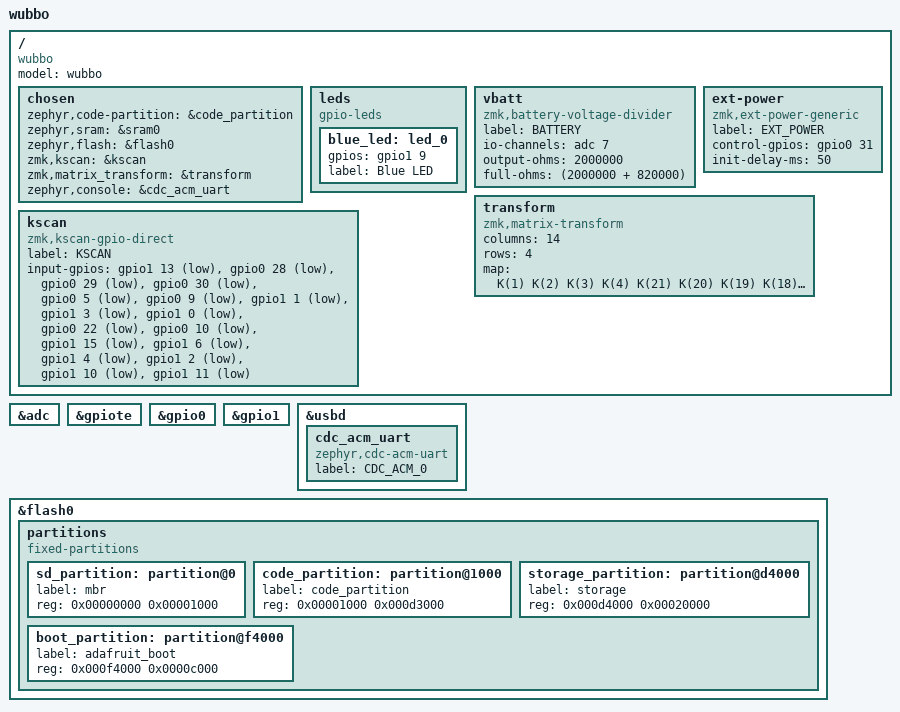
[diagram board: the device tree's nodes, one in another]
/*
 * Copyright (c) 2022 The ZMK Contributors
 *
 * SPDX-License-Identifier: MIT
 */

/dts-v1/;
#include <nordic/nrf52840_qiaa.dtsi>
#include <dt-bindings/zmk/matrix_transform.h>

/ {
	model = "wubbo";
	compatible = "wubbo";

	chosen {
		zephyr,code-partition = &code_partition;
		zephyr,sram = &sram0;
		zephyr,flash = &flash0;
		zmk,kscan = &kscan;
		zmk,matrix_transform = &transform;
		zephyr,console = &cdc_acm_uart;
	};

	leds {
		compatible = "gpio-leds";
		blue_led: led_0 {
			gpios = <&gpio1 9 GPIO_ACTIVE_HIGH>;
			label = "Blue LED";
		};
	};

	vbatt {
		compatible = "zmk,battery-voltage-divider";
		label = "BATTERY";
		io-channels = <&adc 7>;
		output-ohms = <2000000>;
		full-ohms = <(2000000 + 820000)>;
	};

	ext-power {
		compatible = "zmk,ext-power-generic";
		label = "EXT_POWER";
		control-gpios = <&gpio0 31 GPIO_ACTIVE_HIGH>;
		init-delay-ms = <50>;
	};

#define K(n) RC(0,n)
	transform: transform {
		compatible = "zmk,matrix-transform";
		columns = <14>;
		rows = <4>;

		map = <
            K(1)  K(2)  K(3)  K(4)                 K(21) K(20) K(19) K(18) 
K(0)  K(5)  K(6)  K(7)  K(8)  K(9)                 K(26) K(25) K(24) K(23) K(22) K(17)
      K(10) K(11) K(12) K(13) K(14)                K(31) K(30) K(29) K(28) K(27)
                              K(15) K(16)    K(33) K(32)
	>;
	};
	
	kscan: kscan {
		compatible = "zmk,kscan-gpio-direct";
		label = "KSCAN";

        input-gpios
            = <&gpio1 13 (GPIO_ACTIVE_LOW | GPIO_PULL_UP)>
            , <&gpio0 28 (GPIO_ACTIVE_LOW | GPIO_PULL_UP)>
            , <&gpio0 29 (GPIO_ACTIVE_LOW | GPIO_PULL_UP)>
            , <&gpio0 30 (GPIO_ACTIVE_LOW | GPIO_PULL_UP)>
            , <&gpio0  5 (GPIO_ACTIVE_LOW | GPIO_PULL_UP)>

            , <&gpio0  9 (GPIO_ACTIVE_LOW | GPIO_PULL_UP)>
            , <&gpio1  1 (GPIO_ACTIVE_LOW | GPIO_PULL_UP)>
            , <&gpio1  3 (GPIO_ACTIVE_LOW | GPIO_PULL_UP)>
            , <&gpio1  0 (GPIO_ACTIVE_LOW | GPIO_PULL_UP)>
            , <&gpio0 22 (GPIO_ACTIVE_LOW | GPIO_PULL_UP)>

            , <&gpio0  10 (GPIO_ACTIVE_LOW | GPIO_PULL_UP)>
            , <&gpio1  15 (GPIO_ACTIVE_LOW | GPIO_PULL_UP)>
            , <&gpio1   6 (GPIO_ACTIVE_LOW | GPIO_PULL_UP)>
            , <&gpio1   4 (GPIO_ACTIVE_LOW | GPIO_PULL_UP)>
            , <&gpio1   2 (GPIO_ACTIVE_LOW | GPIO_PULL_UP)>

            , <&gpio1 10 (GPIO_ACTIVE_LOW | GPIO_PULL_UP)>
            , <&gpio1 11 (GPIO_ACTIVE_LOW | GPIO_PULL_UP)>
            ;
	};
};

&adc {
	status = "okay";
};

&gpiote {
	status = "okay";
};

&gpio0 {
	status = "okay";
};

&gpio1 {
	status = "okay";
};

&usbd {
  status = "okay";
  cdc_acm_uart: cdc_acm_uart {
    compatible = "zephyr,cdc-acm-uart";
    label = "CDC_ACM_0";
  };
};


&flash0 {
	/*
	 * For more information, see:
	 * http://docs.zephyrproject.org/latest/devices/dts/flash_partitions.html
	 */
	partitions {
		compatible = "fixed-partitions";
		#address-cells = <1>;
		#size-cells = <1>;

		sd_partition: partition@0 {
			label = "mbr";
			reg = <0x00000000 0x00001000>;
		};
		code_partition: partition@1000 {
			label = "code_partition";
			reg = <0x00001000 0x000d3000>;
		};

		storage_partition: partition@d4000 {
			label = "storage";
			reg = <0x000d4000 0x00020000>;
		};

		boot_partition: partition@f4000 {
			label = "adafruit_boot";
			reg = <0x000f4000 0x0000c000>;
		};
	};
};
